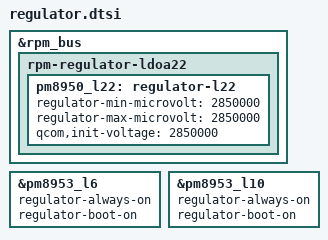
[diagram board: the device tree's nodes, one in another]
&rpm_bus {
	rpm-regulator-ldoa22 {
	pm8950_l22: regulator-l22 {
			regulator-min-microvolt = <2850000>;
			regulator-max-microvolt = <2850000>;
			qcom,init-voltage = <2850000>;
		};
	};
};

&pm8953_l6 {
	regulator-always-on;
	regulator-boot-on;
};

&pm8953_l10 {
	regulator-always-on;
	regulator-boot-on;
};
